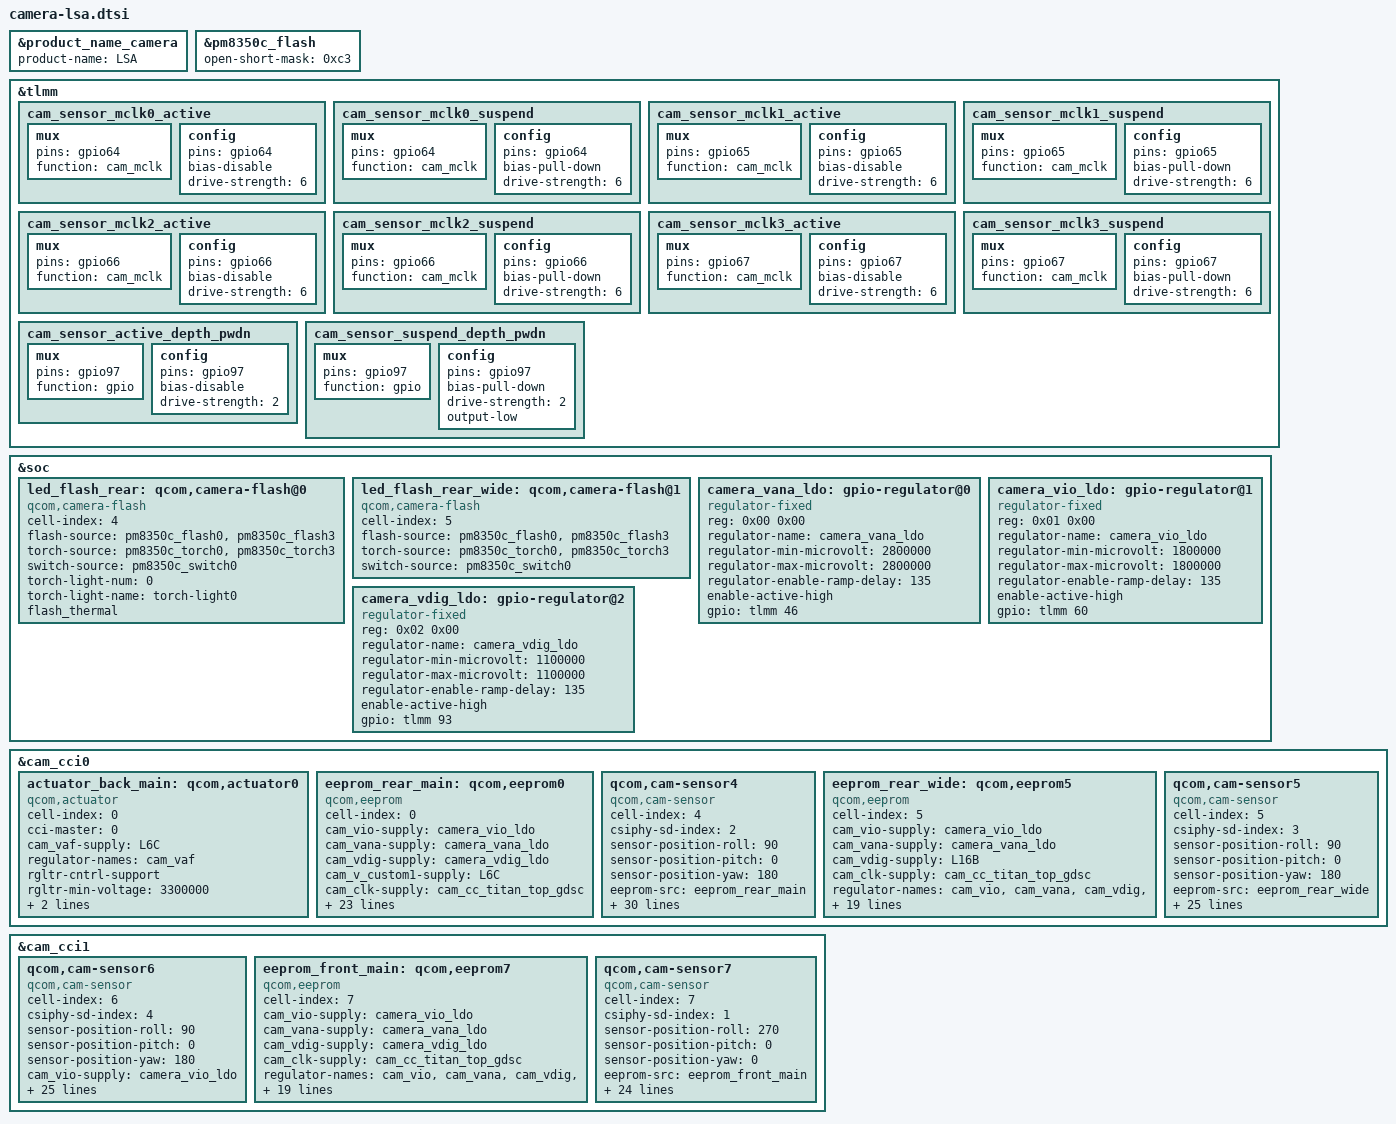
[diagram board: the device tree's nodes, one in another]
#include <dt-bindings/clock/qcom,camcc-yupik.h>
#include "../isolate-qrd.dtsi"

&product_name_camera {
	product-name = "LSA";
};

&pm8350c_flash {
	open-short-mask = /bits/ 8 <0xc3>;
};

&tlmm {
	cam_sensor_mclk0_active: cam_sensor_mclk0_active {
		/* MCLK0 */
		mux {
			pins = "gpio64";
			function = "cam_mclk";
		};

		config {
			pins = "gpio64";
			bias-disable; /* No PULL */
			drive-strength = <6>; /* 6 MA */
		};
	};

	cam_sensor_mclk0_suspend: cam_sensor_mclk0_suspend {
		/* MCLK0 */
		mux {
			pins = "gpio64";
			function = "cam_mclk";
		};

		config {
			pins = "gpio64";
			bias-pull-down; /* PULL DOWN */
			drive-strength = <6>; /* 6 MA */
		};
	};

	cam_sensor_mclk1_active: cam_sensor_mclk1_active {
		/* MCLK1 */
		mux {
			pins = "gpio65";
			function = "cam_mclk";
		};

		config {
			pins = "gpio65";
			bias-disable; /* No PULL */
			drive-strength = <6>; /* 6 MA */
		};
	};

	cam_sensor_mclk1_suspend: cam_sensor_mclk1_suspend {
		/* MCLK1 */
		mux {
			pins = "gpio65";
			function = "cam_mclk";
		};

		config {
			pins = "gpio65";
			bias-pull-down; /* PULL DOWN */
			drive-strength = <6>; /* 6 MA */
		};
	};

	cam_sensor_mclk2_active: cam_sensor_mclk2_active {
		/* MCLK2 */
		mux {
			pins = "gpio66";
			function = "cam_mclk";
		};

		config {
			pins = "gpio66";
			bias-disable; /* No PULL */
			drive-strength = <6>; /* 6 MA */
		};
	};

	cam_sensor_mclk2_suspend: cam_sensor_mclk2_suspend {
		/* MCLK2 */
		mux {
			pins = "gpio66";
			function = "cam_mclk";
		};

		config {
			pins = "gpio66";
			bias-pull-down; /* PULL DOWN */
			drive-strength = <6>; /* 6 MA */
		};
	};

	cam_sensor_mclk3_active: cam_sensor_mclk3_active {
		/* MCLK3 */
		mux {
			pins = "gpio67";
			function = "cam_mclk";
		};

		config {
			pins = "gpio67";
			bias-disable; /* No PULL */
			drive-strength = <6>; /* 6 MA */
		};
	};

	cam_sensor_mclk3_suspend: cam_sensor_mclk3_suspend {
		/* MCLK3 */
		mux {
			pins = "gpio67";
			function = "cam_mclk";
		};

		config {
			pins = "gpio67";
			bias-pull-down; /* PULL DOWN */
			drive-strength = <6>; /* 6 MA */
		};
	};

	cam_sensor_active_depth_pwdn: cam_sensor_active_depth_pwdn {
		/* pwdn enable */
		mux {
			pins = "gpio97";
			function = "gpio";
		};

		config {
			pins = "gpio97";
			bias-disable; /* No PULL */
			drive-strength = <2>; /* 2 MA */
		};
	};

	cam_sensor_suspend_depth_pwdn: cam_sensor_suspend_depth_pwdn {
		/* pwdn disable */
		mux {
			pins = "gpio97";
			function = "gpio";
		};

		config {
			pins = "gpio97";
			bias-pull-down; /* PULL DOWN */
			drive-strength = <2>; /* 2 MA */
			output-low;
		};
	};
};

&soc {
	led_flash_rear: qcom,camera-flash@0 {
		cell-index = <4>;
		compatible = "qcom,camera-flash";
		flash-source = <&pm8350c_flash0 &pm8350c_flash3>;
		torch-source = <&pm8350c_torch0 &pm8350c_torch3>;
		switch-source = <&pm8350c_switch0>;
		torch-light-num = <0>;
		torch-light-name = "torch-light0";
		flash_thermal;
		status = "ok";
	};

	led_flash_rear_wide: qcom,camera-flash@1 {
		cell-index = <5>;
		compatible = "qcom,camera-flash";
		flash-source = <&pm8350c_flash0 &pm8350c_flash3>;
		torch-source = <&pm8350c_torch0 &pm8350c_torch3>;
		switch-source = <&pm8350c_switch0>;
		status = "ok";
	};

	camera_vana_ldo: gpio-regulator@0 {
		compatible = "regulator-fixed";
		reg = <0x00 0x00>;
		regulator-name = "camera_vana_ldo";
		regulator-min-microvolt = <2800000>;
		regulator-max-microvolt = <2800000>;
		regulator-enable-ramp-delay = <135>;
		enable-active-high;
		gpio = <&tlmm 46 0>;
	};

	camera_vio_ldo: gpio-regulator@1 {
		compatible = "regulator-fixed";
		reg = <0x01 0x00>;
		regulator-name = "camera_vio_ldo";
		regulator-min-microvolt = <1800000>;
		regulator-max-microvolt = <1800000>;
		regulator-enable-ramp-delay = <135>;
		enable-active-high;
		gpio = <&tlmm 60 0>;
	};

	camera_vdig_ldo: gpio-regulator@2 {
		compatible = "regulator-fixed";
		reg = <0x02 0x00>;
		regulator-name = "camera_vdig_ldo";
		regulator-min-microvolt = <1100000>;
		regulator-max-microvolt = <1100000>;
		regulator-enable-ramp-delay = <135>;
		enable-active-high;
		gpio = <&tlmm 93 0>;
	};
};

&cam_cci0 {
	actuator_back_main: qcom,actuator0 {
		cell-index = <0>;
		compatible = "qcom,actuator";
		cci-master = <0>;
		cam_vaf-supply = <&L6C>;
		regulator-names = "cam_vaf";
		rgltr-cntrl-support;
		rgltr-min-voltage = <3300000>;
		rgltr-max-voltage = <3300000>;
		rgltr-load-current = <2000000>;
	};

	eeprom_rear_main: qcom,eeprom0 {
		cell-index = <0>;
		compatible = "qcom,eeprom";
		cam_vio-supply = <&camera_vio_ldo>;
		cam_vana-supply = <&camera_vana_ldo>;
		cam_vdig-supply = <&camera_vdig_ldo>;
		cam_v_custom1-supply = <&L6C>;
		cam_clk-supply = <&cam_cc_titan_top_gdsc>;
		regulator-names = "cam_vio", "cam_vana", "cam_vdig", "cam_v_custom1", "cam_clk";
		rgltr-cntrl-support;
		rgltr-min-voltage = <1800000 2800000 1100000 3300000 0>;
		rgltr-max-voltage = <1800000 2800000 1100000 3300000 0>;
		rgltr-load-current = <10000 280000 140000 2000000 0>;
		gpio-no-mux = <0>;
		pinctrl-names = "cam_default", "cam_suspend";
		pinctrl-0 = <&cam_sensor_mclk0_active
			&cam_sensor_active_rst0>;
		pinctrl-1 = <&cam_sensor_mclk0_suspend
			&cam_sensor_suspend_rst0>;
		gpios = <&tlmm 64 0>,
			<&tlmm 20 0>;
		gpio-reset = <1>;
		gpio-req-tbl-num = <0 1>;
		gpio-req-tbl-flags = <1 0>;
		gpio-req-tbl-label = "CAMIF_MCLK0",
			"CAM_RESET0";
		cci-master = <0>;
		status = "ok";
		clocks = <&camcc CAM_CC_MCLK0_CLK>;
		clock-names = "cam_clk";
		clock-cntl-level = "nominal";
		clock-rates = <24000000>;
	};

	/* Rear (Main) */
	qcom,cam-sensor4 {
		cell-index = <4>;
		compatible = "qcom,cam-sensor";
		csiphy-sd-index = <2>;
		sensor-position-roll = <90>;
		sensor-position-pitch = <0>;
		sensor-position-yaw = <180>;
		eeprom-src = <&eeprom_rear_main>;
		actuator-src = <&actuator_back_main>;
		led-flash-src = <&led_flash_rear>;
		cam_vio-supply = <&camera_vio_ldo>;
		cam_vana-supply = <&camera_vana_ldo>;
		cam_vdig-supply = <&camera_vdig_ldo>;
		cam_v_custom1-supply = <&L6C>;
		cam_clk-supply = <&cam_cc_titan_top_gdsc>;
		regulator-names = "cam_vio", "cam_vana", "cam_vdig", "cam_v_custom1", "cam_clk";
		rgltr-cntrl-support;
		rgltr-min-voltage = <1800000 2800000 1100000 3300000 0>;
		rgltr-max-voltage = <1800000 2800000 1100000 3300000 0>;
		rgltr-load-current = <10000 280000 140000 2000000 0>;
		gpio-no-mux = <0>;
		pinctrl-names = "cam_default", "cam_suspend";
		pinctrl-0 = <&cam_sensor_mclk0_active
			&cam_sensor_active_rst0>;
		pinctrl-1 = <&cam_sensor_mclk0_suspend
			&cam_sensor_suspend_rst0>;
		gpios = <&tlmm 64 0>,
			<&tlmm 20 0>;
		gpio-reset = <1>;
		gpio-req-tbl-num = <0 1>;
		gpio-req-tbl-flags = <1 0>;
		gpio-req-tbl-label = "CAMIF_MCLK0",
			"CAM_RESET0";
		cci-master = <0>;
		status = "ok";
		clocks = <&camcc CAM_CC_MCLK0_CLK>;
		clock-names = "cam_clk";
		clock-cntl-level = "nominal";
		clock-rates = <24000000>;
	};

	eeprom_rear_wide: qcom,eeprom5 {
		cell-index = <5>;
		compatible = "qcom,eeprom";
		cam_vio-supply = <&camera_vio_ldo>;
		cam_vana-supply = <&camera_vana_ldo>;
		cam_vdig-supply = <&L16B>;
		cam_clk-supply = <&cam_cc_titan_top_gdsc>;
		regulator-names = "cam_vio", "cam_vana",
			"cam_vdig","cam_clk";
		rgltr-cntrl-support;
		rgltr-min-voltage = <1800000 2800000 1100000 0>;
		rgltr-max-voltage = <1800000 2800000 1100000 0>;
		rgltr-load-current = <10000 280000 140000 0>;
		gpio-no-mux = <0>;
		pinctrl-names = "cam_default", "cam_suspend";
		pinctrl-0 = <&cam_sensor_mclk1_active
			&cam_sensor_active_rst1>;
		pinctrl-1 = <&cam_sensor_mclk1_suspend
			&cam_sensor_suspend_rst1>;
		gpios = <&tlmm 65 0>,
			<&tlmm 21 0>;
		gpio-reset = <1>;
		gpio-req-tbl-num = <0 1>;
		gpio-req-tbl-flags = <1 0>;
		gpio-req-tbl-label = "CAMIF_MCLK1",
			"CAM_RESET1";
		cci-master = <1>;
		status = "ok";
		clocks = <&camcc CAM_CC_MCLK1_CLK>;
		clock-names = "cam_clk";
		clock-cntl-level = "nominal";
		clock-rates = <24000000>;
	};

	/* Rear (Wide) */
	qcom,cam-sensor5 {
		cell-index = <5>;
		compatible = "qcom,cam-sensor";
		csiphy-sd-index = <3>;
		sensor-position-roll = <90>;
		sensor-position-pitch = <0>;
		sensor-position-yaw = <180>;
		eeprom-src = <&eeprom_rear_wide>;
		led-flash-src = <&led_flash_rear_wide>;
		cam_vio-supply = <&camera_vio_ldo>;
		cam_vana-supply = <&camera_vana_ldo>;
		cam_vdig-supply = <&L16B>;
		cam_clk-supply = <&cam_cc_titan_top_gdsc>;
		regulator-names = "cam_vio", "cam_vana",
			"cam_vdig","cam_clk";
		rgltr-cntrl-support;
		rgltr-min-voltage = <1800000 2800000 1100000 0>;
		rgltr-max-voltage = <1800000 2800000 1100000 0>;
		rgltr-load-current = <10000 280000 140000 0>;
		gpio-no-mux = <0>;
		pinctrl-names = "cam_default", "cam_suspend";
		pinctrl-0 = <&cam_sensor_mclk1_active
			&cam_sensor_active_rst1>;
		pinctrl-1 = <&cam_sensor_mclk1_suspend
			&cam_sensor_suspend_rst1>;
		gpios = <&tlmm 65 0>,
			<&tlmm 21 0>;
		gpio-reset = <1>;
		gpio-req-tbl-num = <0 1>;
		gpio-req-tbl-flags = <1 0>;
		gpio-req-tbl-label = "CAMIF_MCLK1",
			"CAM_RESET1";
		cci-master = <1>;
		status = "ok";
		clocks = <&camcc CAM_CC_MCLK1_CLK>;
		clock-names = "cam_clk";
		clock-cntl-level = "nominal";
		clock-rates = <24000000>;
	};
};

&cam_cci1 {
	/* Rear (Depth) */
	qcom,cam-sensor6 {
		cell-index = <6>;
		compatible = "qcom,cam-sensor";
		csiphy-sd-index = <4>;
		sensor-position-roll = <90>;
		sensor-position-pitch = <0>;
		sensor-position-yaw = <180>;
		cam_vio-supply = <&camera_vio_ldo>;
		cam_vana-supply = <&camera_vana_ldo>;
		cam_clk-supply = <&cam_cc_titan_top_gdsc>;
		regulator-names = "cam_vio", "cam_vana","cam_clk";
		rgltr-cntrl-support;
		rgltr-min-voltage = <1800000 2800000 0>;
		rgltr-max-voltage = <1800000 2800000 0>;
		rgltr-load-current = <10000 280000 0>;
		gpio-no-mux = <0>;
		pinctrl-names = "cam_default", "cam_suspend";
		pinctrl-0 = <&cam_sensor_mclk2_active
			&cam_sensor_active_rst2
			&cam_sensor_active_depth_pwdn>;
		pinctrl-1 = <&cam_sensor_mclk2_suspend
			&cam_sensor_suspend_rst2
			&cam_sensor_suspend_depth_pwdn>;
		gpios = <&tlmm 66 0>,
			<&tlmm 77 0>,
			<&tlmm 97 0>;
		gpio-reset = <1>;
		gpio-custom1 = <2>;
		gpio-req-tbl-num = <0 1 2>;
		gpio-req-tbl-flags = <1 0 0>;
		gpio-req-tbl-label = "CAMIF_MCLK2",
			"CAM_RESET2",
			"CAM_CUSTOM1";
		cci-master = <0>;
		status = "ok";
		clocks = <&camcc CAM_CC_MCLK2_CLK>;
		clock-names = "cam_clk";
		clock-cntl-level = "nominal";
		clock-rates = <24000000>;
	};

	eeprom_front_main: qcom,eeprom7 {
		cell-index = <7>;
		compatible = "qcom,eeprom";
		cam_vio-supply = <&camera_vio_ldo>;
		cam_vana-supply = <&camera_vana_ldo>;
		cam_vdig-supply = <&camera_vdig_ldo>;
		cam_clk-supply = <&cam_cc_titan_top_gdsc>;
		regulator-names = "cam_vio", "cam_vana", "cam_vdig",
			"cam_clk";
		rgltr-cntrl-support;
		rgltr-min-voltage = <1800000 2800000 1100000 0>;
		rgltr-max-voltage = <1800000 2900000 1100000 0>;
		rgltr-load-current = <5000 35000 301000 0>;
		gpio-no-mux = <0>;
		pinctrl-names = "cam_default", "cam_suspend";
		pinctrl-0 = <&cam_sensor_mclk3_active
			&cam_sensor_active_rst3>;
		pinctrl-1 = <&cam_sensor_mclk3_suspend
			&cam_sensor_suspend_rst3>;
		gpios = <&tlmm 67 0>,
			<&tlmm 78 0>;
		gpio-reset = <1>;
		gpio-req-tbl-num = <0 1>;
		gpio-req-tbl-flags = <1 0>;
		gpio-req-tbl-label = "CAMIF_MCLK3",
			"CAM_RESET3";
		cci-master = <1>;
		status = "ok";
		clocks = <&camcc CAM_CC_MCLK3_CLK>;
		clock-names = "cam_clk";
		clock-cntl-level = "nominal";
		clock-rates = <24000000>;
	};

	/* Front */
	qcom,cam-sensor7 {
		cell-index = <7>;
		compatible = "qcom,cam-sensor";
		csiphy-sd-index = <1>;
		sensor-position-roll = <270>;
		sensor-position-pitch = <0>;
		sensor-position-yaw = <0>;
		eeprom-src = <&eeprom_front_main>;
		cam_vio-supply = <&camera_vio_ldo>;
		cam_vana-supply = <&camera_vana_ldo>;
		cam_vdig-supply = <&camera_vdig_ldo>;
		cam_clk-supply = <&cam_cc_titan_top_gdsc>;
		regulator-names = "cam_vio", "cam_vana", "cam_vdig",
			"cam_clk";
		rgltr-cntrl-support;
		rgltr-min-voltage = <1800000 2800000 1100000 0>;
		rgltr-max-voltage = <1800000 2900000 1100000 0>;
		rgltr-load-current = <5000 35000 301000 0>;
		gpio-no-mux = <0>;
		pinctrl-names = "cam_default", "cam_suspend";
		pinctrl-0 = <&cam_sensor_mclk3_active
			&cam_sensor_active_rst3>;
		pinctrl-1 = <&cam_sensor_mclk3_suspend
			&cam_sensor_suspend_rst3>;
		gpios = <&tlmm 67 0>,
			<&tlmm 78 0>;
		gpio-reset = <1>;
		gpio-req-tbl-num = <0 1>;
		gpio-req-tbl-flags = <1 0>;
		gpio-req-tbl-label = "CAMIF_MCLK3",
			"CAM_RESET3";
		cci-master = <1>;
		status = "ok";
		clocks = <&camcc CAM_CC_MCLK3_CLK>;
		clock-names = "cam_clk";
		clock-cntl-level = "nominal";
		clock-rates = <24000000>;
	};
};
